AUTOSAR XML (schema 4-0-3)
package /BswM/ServiceSwComponentTypes
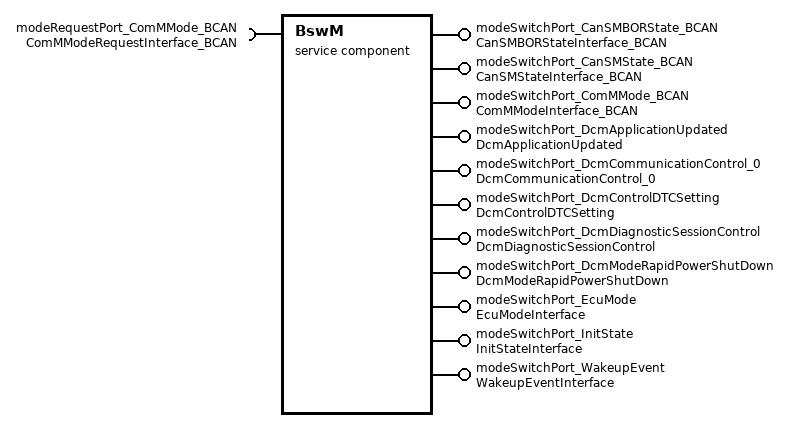
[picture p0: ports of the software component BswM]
  service sw component type BswM
    require port modeRequestPort_ComMMode_BCAN: nonqueued-receiver-com-spec=ComMMode_BCAN, required-interface=ComMModeRequestInterface_BCAN
    11 x provide port:
      modeSwitchPort_CanSMBORState_BCAN: mode-switch-sender-com-spec{enhanced-mode-api=false, mode-group=CanSMBORState_BCAN, queue-length=1}, provided-interface=CanSMBORStateInterface_BCAN
      modeSwitchPort_CanSMState_BCAN: mode-switch-sender-com-spec{enhanced-mode-api=false, mode-group=CanSMState_BCAN, queue-length=1}, provided-interface=CanSMStateInterface_BCAN
      modeSwitchPort_ComMMode_BCAN: mode-switch-sender-com-spec{enhanced-mode-api=false, mode-group=ComMMode_BCAN, queue-length=1}, provided-interface=ComMModeInterface_BCAN
      modeSwitchPort_DcmApplicationUpdated: mode-switch-sender-com-spec{enhanced-mode-api=false, mode-group=DcmApplicationUpdated, queue-length=1}, provided-interface=DcmApplicationUpdated
      modeSwitchPort_DcmCommunicationControl_0: mode-switch-sender-com-spec{enhanced-mode-api=false, mode-group=DcmCommunicationControl_0, queue-length=1}, provided-interface=DcmCommunicationControl_0
      modeSwitchPort_DcmControlDTCSetting: mode-switch-sender-com-spec{enhanced-mode-api=false, mode-group=DcmControlDTCSetting, queue-length=1}, provided-interface=DcmControlDTCSetting
      modeSwitchPort_DcmDiagnosticSessionControl: mode-switch-sender-com-spec{enhanced-mode-api=false, mode-group=DcmDiagnosticSessionControl, queue-length=1}, provided-interface=DcmDiagnosticSessionControl
      modeSwitchPort_DcmModeRapidPowerShutDown: mode-switch-sender-com-spec{enhanced-mode-api=false, mode-group=DcmModeRapidPowerShutDown, queue-length=1}, provided-interface=DcmModeRapidPowerShutDown
      modeSwitchPort_EcuMode: mode-switch-sender-com-spec{enhanced-mode-api=false, mode-group=EcuMode, queue-length=1}, provided-interface=EcuModeInterface
      modeSwitchPort_InitState: mode-switch-sender-com-spec{enhanced-mode-api=false, mode-group=InitState, queue-length=1}, provided-interface=InitStateInterface
      modeSwitchPort_WakeupEvent: mode-switch-sender-com-spec{enhanced-mode-api=false, mode-group=WakeupEvent, queue-length=1}, provided-interface=WakeupEventInterface
    behavior SwcIB_BswM: data-type-mapping=[MAP_AppMode, MAP_CanSMBORState, DcmDiagnosticSessionControl, MAP_PduGroup, MAP_WakeupEvent, MAP_LinSMState, MAP_InitState, EcuModeMap, DcmApplicationUpdated, MAP_ComMMode], handle-termination-and-restart=NO-SUPPORT
      data received event DRE_BswM_Immediate_SwcModeRequest_ComMMode_BCAN_modeRequestPort_ComMMode_BCAN_ComMMode_BCAN: start-on-event=BswM_Immediate_SwcModeRequest_ComMMode_BCAN, data=modeRequestPort_ComMMode_BCAN.ComMMode_BCAN
      12 x runnable:
        BswM_ActionList_RteSwitch_CanSMBORState_BCAN: can-be-invoked-concurrently=true
          mode switch point MSP_BswM_ActionList_RteSwitch_CanSMBORState_BCAN_modeSwitchPort_CanSMBORState_BCAN_CanSMBORState_BCAN: category=TOOL_CONFIGURED, mode-group=modeSwitchPort_CanSMBORState_BCAN.CanSMBORState_BCAN
        BswM_ActionList_RteSwitch_CanSMState_BCAN: can-be-invoked-concurrently=true
          mode switch point MSP_BswM_ActionList_RteSwitch_CanSMState_BCAN_modeSwitchPort_CanSMState_BCAN_CanSMState_BCAN: category=TOOL_CONFIGURED, mode-group=modeSwitchPort_CanSMState_BCAN.CanSMState_BCAN
        BswM_ActionList_RteSwitch_ComMMode_BCAN: can-be-invoked-concurrently=true
          mode switch point MSP_BswM_ActionList_RteSwitch_ComMMode_BCAN_modeSwitchPort_ComMMode_BCAN_ComMMode_BCAN: category=TOOL_CONFIGURED, mode-group=modeSwitchPort_ComMMode_BCAN.ComMMode_BCAN
        BswM_ActionList_RteSwitch_DcmApplicationUpdated: can-be-invoked-concurrently=true
          mode switch point MSP_BswM_ActionList_RteSwitch_DcmApplicationUpdated_modeSwitchPort_DcmApplicationUpdated_DcmApplicationUpdated: category=TOOL_CONFIGURED, mode-group=modeSwitchPort_DcmApplicationUpdated.DcmApplicationUpdated
        BswM_ActionList_RteSwitch_DcmCommunicationControl_0: can-be-invoked-concurrently=true
          mode switch point MSP_BswM_ActionList_RteSwitch_DcmCommunicationControl_0_modeSwitchPort_DcmCommunicationControl_0_DcmCommunicationControl_0: category=TOOL_CONFIGURED, mode-group=modeSwitchPort_DcmCommunicationControl_0.DcmCommunicationControl_0
        BswM_ActionList_RteSwitch_DcmControlDTCSetting: can-be-invoked-concurrently=true
          mode switch point MSP_BswM_ActionList_RteSwitch_DcmControlDTCSetting_modeSwitchPort_DcmControlDTCSetting_DcmControlDTCSetting: category=TOOL_CONFIGURED, mode-group=modeSwitchPort_DcmControlDTCSetting.DcmControlDTCSetting
        BswM_ActionList_RteSwitch_DcmDiagnosticSessionControl: can-be-invoked-concurrently=true
          mode switch point MSP_BswM_ActionList_RteSwitch_DcmDiagnosticSessionControl_modeSwitchPort_DcmDiagnosticSessionControl_DcmDiagnosticSessionControl: category=TOOL_CONFIGURED, mode-group=modeSwitchPort_DcmDiagnosticSessionControl.DcmDiagnosticSessionControl
        BswM_ActionList_RteSwitch_DcmModeRapidPowerShutDown: can-be-invoked-concurrently=true
          mode switch point MSP_BswM_ActionList_RteSwitch_DcmModeRapidPowerShutDown_modeSwitchPort_DcmModeRapidPowerShutDown_DcmModeRapidPowerShutDown: category=TOOL_CONFIGURED, mode-group=modeSwitchPort_DcmModeRapidPowerShutDown.DcmModeRapidPowerShutDown
        BswM_ActionList_RteSwitch_EcuMode: can-be-invoked-concurrently=true
          mode switch point MSP_BswM_ActionList_RteSwitch_EcuMode_modeSwitchPort_EcuMode_EcuMode: category=TOOL_CONFIGURED, mode-group=modeSwitchPort_EcuMode.EcuMode
        BswM_ActionList_RteSwitch_InitState: can-be-invoked-concurrently=true
          mode switch point MSP_BswM_ActionList_RteSwitch_InitState_modeSwitchPort_InitState_InitState: category=TOOL_CONFIGURED, mode-group=modeSwitchPort_InitState.InitState
        BswM_ActionList_RteSwitch_WakeupEvent: can-be-invoked-concurrently=true
          mode switch point MSP_BswM_ActionList_RteSwitch_WakeupEvent_modeSwitchPort_WakeupEvent_WakeupEvent: category=TOOL_CONFIGURED, mode-group=modeSwitchPort_WakeupEvent.WakeupEvent
        BswM_Immediate_SwcModeRequest_ComMMode_BCAN
          data-receive-point-by-arguments:
            access DRPBA_BswM_Immediate_SwcModeRequest_ComMMode_BCAN_modeRequestPort_ComMMode_BCAN_ComMMode_BCAN: category=TOOL_CONFIGURED, accessed-variable=modeRequestPort_ComMMode_BCAN.ComMMode_BCAN
  swc implementation SwcImplementation_BswM: programming-language=C, swc-bsw-mapping=SwcBswMapping_BswM, behavior=SwcIB_BswM
package /BswM/SwcBswMappings
  swc bsw mapping SwcBswMapping_BswM: bsw-behavior=BswIB_BswM, swc-behavior=SwcIB_BswM
